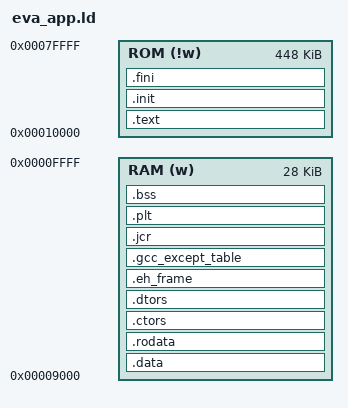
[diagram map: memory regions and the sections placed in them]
OUTPUT_FORMAT("elf32-xstormy16", "elf32-xstormy16",
	      "elf32-xstormy16")
OUTPUT_ARCH(xstormy16)
ENTRY(_start)
GROUP(-lc -leva_app -lgcc)

MEMORY 
{
  RAM   (w)  : ORIGIN = 0x9000,  LENGTH = 0x7000
  ROM   (!w)  : ORIGIN = 0x10000, LENGTH = 0x70000
}

SECTIONS
{
  __stack = 2 ;
  __malloc_start = 0x800;
  .data    :
  {
    __rdata = .;
    __data = .;
    *(.data)
    *(.data.*)
    *(.gnu.linkonce.d.*)
    SORT(CONSTRUCTORS)
  } > RAM
  /* Read-only sections */
  .rodata   : { *(.rodata) *(.rodata.*) *(.gnu.linkonce.r.*) } > RAM
  .ctors   : 
  {
    /* gcc uses crtbegin.o to find the start of
       the constructors, so we make sure it is
       first.  Because this is a wildcard, it
       doesn't matter if the user does not
       actually link against crtbegin.o; the
       linker won't look for a file to match a
       wildcard.  The wildcard also means that it
       doesn't matter which directory crtbegin.o
       is in.  */
    KEEP (*crtbegin.o(.ctors))
    /* We don't want to include the .ctor section from
       from the crtend.o file until after the sorted ctors.
       The .ctor section from the crtend file contains the
       end of ctors marker and it must be last */
    KEEP (*(EXCLUDE_FILE (*crtend.o ) .ctors))
    KEEP (*(SORT(.ctors.*)))
    KEEP (*(.ctors))
  } > RAM
   .dtors         :
  {
    KEEP (*crtbegin.o(.dtors))
    KEEP (*(EXCLUDE_FILE (*crtend.o ) .dtors))
    KEEP (*(SORT(.dtors.*)))
    KEEP (*(.dtors))
  } > RAM
  .eh_frame : { KEEP (*(.eh_frame)) } > RAM
  .gcc_except_table : { *(.gcc_except_table) } > RAM
  .jcr : { *(.jcr) } > RAM
  .plt : { *(.plt) } > RAM
  _edata = .;
  PROVIDE (edata = .);
  __bss_start = .;
  .bss       :
  {
   *(.dynbss)
   *(.bss)
   *(.bss.*)
   *(.gnu.linkonce.b.*)
   *(COMMON)
   /* Align here to ensure that the .bss section occupies space up to
      _end.  Align after .bss to ensure correct alignment even if the
      .bss section disappears because there are no input sections.  */
   . = ALIGN(2);
  } > RAM
  . = ALIGN(2);
  _end = .;
  PROVIDE (end = .);
  .text      :
  {
    *(.int_vec)
    *(.text)
    *(.text.*)
    *(.stub)
    /* .gnu.warning sections are handled specially by elf32.em.  */
    *(.gnu.warning)
    *(.gnu.linkonce.t.*)
  } > ROM =0
  .init          : 
  { 
    KEEP (*(.init))
  } > ROM =0
  .fini      :
  {
    KEEP (*(.fini))
  } > ROM =0
  PROVIDE (__etext = .);
  PROVIDE (_etext = .);
  PROVIDE (etext = .);
  /* Stabs debugging sections.  */
  .stab 0 : { *(.stab) }
  .stabstr 0 : { *(.stabstr) }
  .stab.excl 0 : { *(.stab.excl) }
  .stab.exclstr 0 : { *(.stab.exclstr) }
  .stab.index 0 : { *(.stab.index) }
  .stab.indexstr 0 : { *(.stab.indexstr) }
  .comment 0 : { *(.comment) }
  /* DWARF debug sections.
     Symbols in the DWARF debugging sections are relative to the beginning
     of the section so we begin them at 0.  */
  /* DWARF 1 */
  .debug          0 : { *(.debug) }
  .line           0 : { *(.line) }
  /* GNU DWARF 1 extensions */
  .debug_srcinfo  0 : { *(.debug_srcinfo) }
  .debug_sfnames  0 : { *(.debug_sfnames) }
  /* DWARF 1.1 and DWARF 2 */
  .debug_aranges  0 : { *(.debug_aranges) }
  .debug_pubnames 0 : { *(.debug_pubnames) }
  /* DWARF 2 */
  .debug_info     0 : { *(.debug_info) *(.gnu.linkonce.wi.*) }
  .debug_abbrev   0 : { *(.debug_abbrev) }
  .debug_line     0 : { *(.debug_line) }
  .debug_frame    0 : { *(.debug_frame) }
  .debug_str      0 : { *(.debug_str) }
  .debug_loc      0 : { *(.debug_loc) }
  .debug_macinfo  0 : { *(.debug_macinfo) }
  .debug_ranges   0 : { *(.debug_ranges) }
  /* SGI/MIPS DWARF 2 extensions */
  .debug_weaknames 0 : { *(.debug_weaknames) }
  .debug_funcnames 0 : { *(.debug_funcnames) }
  .debug_typenames 0 : { *(.debug_typenames) }
  .debug_varnames  0 : { *(.debug_varnames) }
  /* These must appear regardless of  .  */
}
